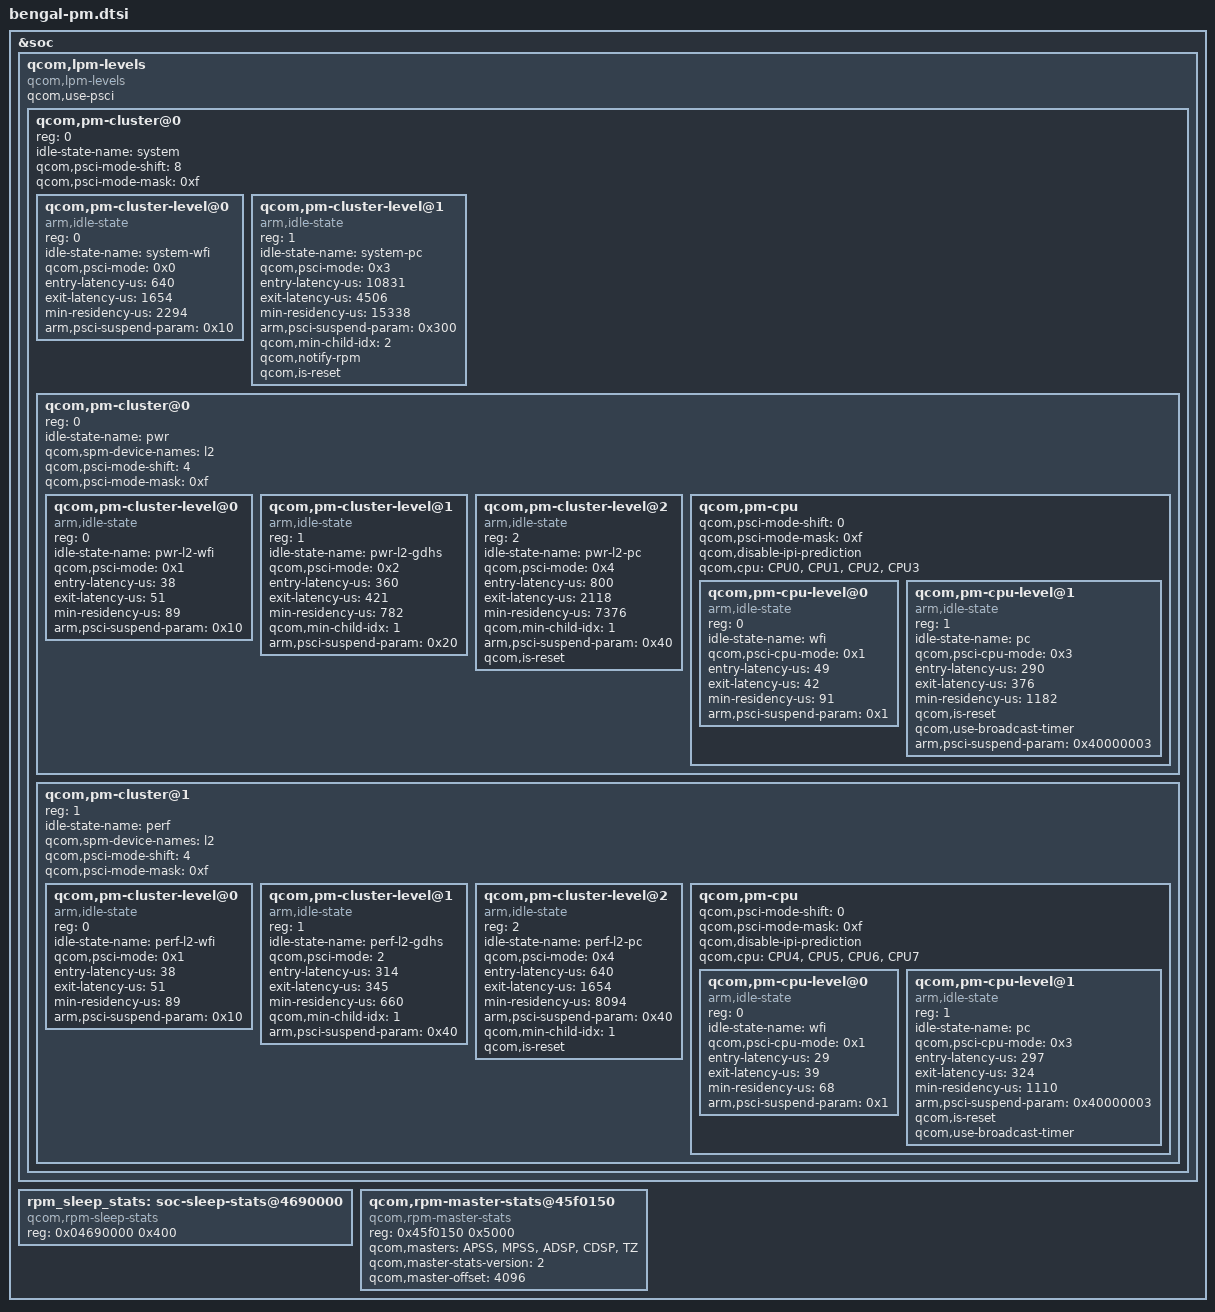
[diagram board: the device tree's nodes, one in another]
&soc {
	qcom,lpm-levels {
		compatible = "qcom,lpm-levels";
		qcom,use-psci;
		#address-cells = <1>;
		#size-cells = <0>;
		qcom,pm-cluster@0 {
			reg = <0>;
			#address-cells = <1>;
			#size-cells = <0>;
			idle-state-name = "system";
			qcom,psci-mode-shift = <8>;
			qcom,psci-mode-mask = <0xf>;

			qcom,pm-cluster-level@0 {
				reg = <0>;
				compatible = "arm,idle-state";
				idle-state-name = "system-wfi";
				qcom,psci-mode = <0x0>;
				entry-latency-us = <640>;
				exit-latency-us = <1654>;
				min-residency-us = <2294>;
				arm,psci-suspend-param = <0x10>;
			};

			qcom,pm-cluster-level@1 { /* E3 */
				reg = <1>;
				compatible = "arm,idle-state";
				idle-state-name = "system-pc";
				qcom,psci-mode = <0x3>;
				entry-latency-us = <10831>;
				exit-latency-us = <4506>;
				min-residency-us = <15338>;
				arm,psci-suspend-param = <0x300>;
				qcom,min-child-idx = <2>;
				qcom,notify-rpm;
				qcom,is-reset;
			};

			qcom,pm-cluster@0 {
				reg = <0>;
				#address-cells = <1>;
				#size-cells = <0>;
				idle-state-name = "pwr";
				qcom,spm-device-names = "l2";
				qcom,psci-mode-shift = <4>;
				qcom,psci-mode-mask = <0xf>;

				qcom,pm-cluster-level@0 { /* D1 */
					reg = <0>;
					compatible = "arm,idle-state";
					idle-state-name = "pwr-l2-wfi";
					qcom,psci-mode = <0x1>;
					entry-latency-us = <38>;
					exit-latency-us = <51>;
					min-residency-us = <89>;
					arm,psci-suspend-param = <0x10>;
				};

				qcom,pm-cluster-level@1 { /* D3G */
					reg = <1>;
					compatible = "arm,idle-state";
					idle-state-name = "pwr-l2-gdhs";
					qcom,psci-mode = <0x2>;
					entry-latency-us = <360>;
					exit-latency-us = <421>;
					min-residency-us = <782>;
					qcom,min-child-idx = <1>;
					arm,psci-suspend-param = <0x20>;
				};

				qcom,pm-cluster-level@2 { /* D3 */
					reg = <2>;
					compatible = "arm,idle-state";
					idle-state-name = "pwr-l2-pc";
					qcom,psci-mode = <0x4>;
					entry-latency-us = <800>;
					exit-latency-us = <2118>;
					min-residency-us = <7376>;
					qcom,min-child-idx = <1>;
					arm,psci-suspend-param = <0x40>;
					qcom,is-reset;
				};

				qcom,pm-cpu {
					#address-cells = <1>;
					#size-cells = <0>;
					qcom,psci-mode-shift = <0>;
					qcom,psci-mode-mask = <0xf>;
					qcom,disable-ipi-prediction;
					qcom,cpu = <&CPU0 &CPU1 &CPU2 &CPU3>;

					qcom,pm-cpu-level@0 { /* C1 */
						reg = <0>;
						compatible = "arm,idle-state";
						idle-state-name = "wfi";
						qcom,psci-cpu-mode = <0x1>;
						entry-latency-us = <49>;
						exit-latency-us = <42>;
						min-residency-us = <91>;
						arm,psci-suspend-param = <0x1>;
					};

					qcom,pm-cpu-level@1 {  /* C3 */
						reg = <1>;
						compatible = "arm,idle-state";
						idle-state-name = "pc";
						qcom,psci-cpu-mode = <0x3>;
						entry-latency-us = <290>;
						exit-latency-us = <376>;
						min-residency-us = <1182>;
						qcom,is-reset;
						qcom,use-broadcast-timer;
						arm,psci-suspend-param = <0x40000003>;
					};
				};
			};

			qcom,pm-cluster@1 {
				reg = <1>;
				#address-cells = <1>;
				#size-cells = <0>;
				idle-state-name = "perf";
				qcom,spm-device-names = "l2";
				qcom,psci-mode-shift = <4>;
				qcom,psci-mode-mask = <0xf>;

				qcom,pm-cluster-level@0 {  /* D1 */
					reg = <0>;
					compatible = "arm,idle-state";
					idle-state-name = "perf-l2-wfi";
					qcom,psci-mode = <0x1>;
					entry-latency-us = <38>;
					exit-latency-us = <51>;
					min-residency-us = <89>;
					arm,psci-suspend-param = <0x10>;
				};

				qcom,pm-cluster-level@1 { /* D3G*/
					reg = <1>;
					compatible = "arm,idle-state";
					idle-state-name = "perf-l2-gdhs";
					qcom,psci-mode = <2>;
					entry-latency-us = <314>;
					exit-latency-us = <345>;
					min-residency-us = <660>;
					qcom,min-child-idx = <1>;
					arm,psci-suspend-param = <0x40>;
				};

				qcom,pm-cluster-level@2 { /* D3 */
					reg = <2>;
					compatible = "arm,idle-state";
					idle-state-name = "perf-l2-pc";
					qcom,psci-mode = <0x4>;
					entry-latency-us = <640>;
					exit-latency-us = <1654>;
					min-residency-us = <8094>;
					arm,psci-suspend-param = <0x40>;
					qcom,min-child-idx = <1>;
					qcom,is-reset;
				};

				qcom,pm-cpu {
					#address-cells = <1>;
					#size-cells = <0>;
					qcom,psci-mode-shift = <0>;
					qcom,psci-mode-mask = <0xf>;
					qcom,disable-ipi-prediction;
					qcom,cpu = <&CPU4 &CPU5 &CPU6 &CPU7>;

					qcom,pm-cpu-level@0 { /* C1 */
						reg = <0>;
						compatible = "arm,idle-state";
						idle-state-name = "wfi";
						qcom,psci-cpu-mode = <0x1>;
						entry-latency-us = <29>;
						exit-latency-us = <39>;
						min-residency-us = <68>;
						arm,psci-suspend-param = <0x1>;
					};

					qcom,pm-cpu-level@1 { /* C3 */
						reg = <1>;
						compatible = "arm,idle-state";
						idle-state-name = "pc";
						qcom,psci-cpu-mode = <0x3>;
						entry-latency-us = <297>;
						exit-latency-us = <324>;
						min-residency-us = <1110>;
						arm,psci-suspend-param = <0x40000003>;
						qcom,is-reset;
						qcom,use-broadcast-timer;
					};
				};
			};
		};
	};

	rpm_sleep_stats: soc-sleep-stats@4690000 {
		compatible = "qcom,rpm-sleep-stats";
		reg = <0x04690000 0x400>;
	};

	qcom,rpm-master-stats@45f0150 {
		compatible = "qcom,rpm-master-stats";
		reg = <0x45f0150 0x5000>;
		qcom,masters = "APSS", "MPSS", "ADSP", "CDSP", "TZ";
		qcom,master-stats-version = <2>;
		qcom,master-offset = <4096>;
	};
};

